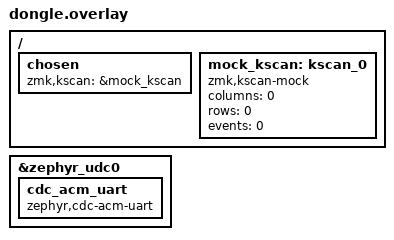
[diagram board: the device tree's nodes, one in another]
/* dongle.overlay */
/ {
    chosen {
        zmk,kscan = &mock_kscan;
        /* console 설정은 스니펫한테 맡기고 비워둡니다 */
    };

    mock_kscan: kscan_0 {
        compatible = "zmk,kscan-mock";
        columns = <0>;
        rows = <0>;
        events = <0>;
    };
};

/* [핵심] 아까 지우라고 했던 이 부분을 다시 넣어야 합니다! */
/* USB 컨트롤러에 가상의 시리얼 포트(cdc_acm_uart)를 달아주는 코드 */
&zephyr_udc0 {
    cdc_acm_uart: cdc_acm_uart {
        compatible = "zephyr,cdc-acm-uart";
    };
};
